VERSION ""

NS_ :

BS_:

BU_: BMS Third_Party_Device

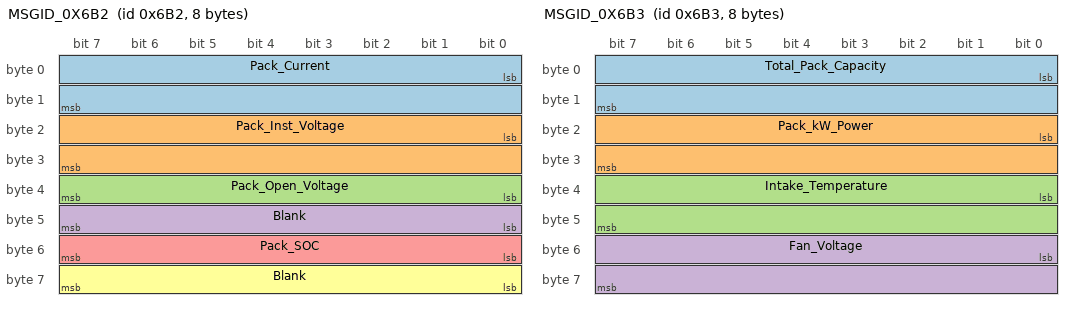
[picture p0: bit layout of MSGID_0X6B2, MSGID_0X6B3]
BO_ 1714 MSGID_0X6B2: 8 BMS
 SG_ Pack_Current : 0|16@1+ (0.1,0) [0|0] "Amps"  Third_Party_Device
 SG_ Pack_Inst_Voltage : 16|16@1+ (0.1,0) [0|0] "Volts"  Third_Party_Device
 SG_ Pack_Open_Voltage : 39|8@0+ (0.1,0) [0|0] "Volts"  Third_Party_Device
 SG_ Blank : 47|8@0+ (1.0,0) [0|0] ""  Third_Party_Device
 SG_ Pack_SOC : 48|8@1+ (0.5,0) [0|0] "Percent"  Third_Party_Device
 SG_ Blank : 63|8@0+ (1.0,0) [0|0] ""  Third_Party_Device

BO_ 1715 MSGID_0X6B3: 8 BMS
 SG_ Total_Pack_Capacity : 0|16@1+ (0.1,0) [0|0] "Ahr"  Third_Party_Device
 SG_ Pack_kW_Power : 16|16@1+ (0.1,0) [0|0] "kW"  Third_Party_Device
 SG_ Intake_Temperature : 32|16@1+ (1.0,0) [0|0] "Celsius"  Third_Party_Device
 SG_ Fan_Voltage : 48|16@1+ (0.01,0) [0|0] "Volts"  Third_Party_Device

BO_ 1 MSGID_0X1: 4 BMS
 SG_ DTC_Flags_1 : 0|16@1+ (1.0,0) [0|0] ""  Third_Party_Device
 SG_ DTC_Flags_2 : 16|16@1+ (1.0,0) [0|0] ""  Third_Party_Device

CM_ BO_ 1714 "This ID Transmits at 2000 ms.";
CM_ BO_ 1715 "This ID Transmits at 2000 ms.";
CM_ BO_ 1 "This ID Transmits at 8 ms.";
